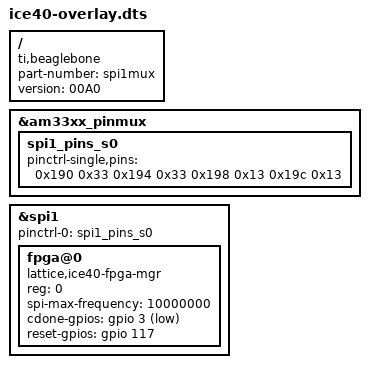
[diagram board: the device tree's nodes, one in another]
/*
 * Copyright (c) 2017 Patryk Mezydlo <pmezydlo - mezydlo.p@gmail.com>
 *
 */

/dts-v1/;
/plugin/;

/* BeagleWire programmer */
/ {
	compatible = "ti,beaglebone", "ti,beaglebone-black";
	part-number = "spi1mux";
	version = "00A0";

	fragment@0 {
		target = <&am33xx_pinmux>;
		__overlay__ {
			spi1_pins_s0: spi1_pins_s0 {
				pinctrl-single,pins = <
					0x190 0x33      /* mcasp0_aclkx.spi1_sclk, INPUT_PULLUP | MODE3 */
					0x194 0x33      /* mcasp0_fsx.spi1_d0, INPUT_PULLUP | MODE3 */
					0x198 0x13      /* mcasp0_axr0.spi1_d1, OUTPUT_PULLUP | MODE3 */
					0x19c 0x13      /* mcasp0_ahclkr.spi1_cs0, OUTPUT_PULLUP | MODE3 */
				>;
			};
		};
	};


	fragment@1 {
		target = <&spi1>;
		__overlay__ {
			#address-cells = <1>;
			#size-cells = <0>;
		        status = "okay";
			pinctrl-names = "default";
			pinctrl-0 = <&spi1_pins_s0>;
			fpga@0 {
				compatible = "lattice,ice40-fpga-mgr";
				reg = <0>;
				spi-max-frequency = <10000000>;
				cdone-gpios = <&gpio 3 1>;
				reset-gpios = <&gpio 117 0>;
			};
		};
	};
};
